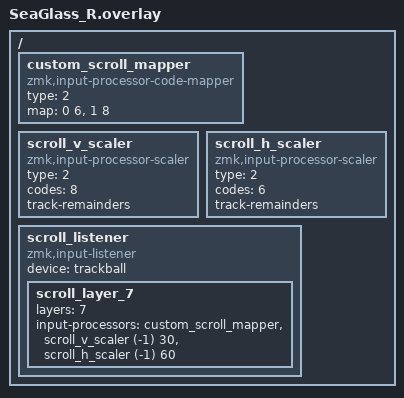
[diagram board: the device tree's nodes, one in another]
/ {
    /* 1. 移動をスクロールに変換するマッパー */
    custom_scroll_mapper: custom_scroll_mapper {
        compatible = "zmk,input-processor-code-mapper";
        #input-processor-cells = <0>;
        type = <2>; 
        map = <0 6>, <1 8>;
    };

    /* =======================================
       2. 感度（距離）を調整するスケーラーを2つに分割！
       ======================================= */
       
    /* ▼ 縦スクロール（上下）用の調整器 */
    scroll_v_scaler: scroll_v_scaler {
        compatible = "zmk,input-processor-scaler";
        #input-processor-cells = <2>;
        type = <2>;
        codes = <8>; /* 8 = 縦スクロール */
        track-remainders;
    };

    /* ▼ 横スクロール（左右）用の調整器 */
    scroll_h_scaler: scroll_h_scaler {
        compatible = "zmk,input-processor-scaler";
        #input-processor-cells = <2>;
        type = <2>;
        codes = <6>; /* 6 = 横スクロール(Pan) */
        track-remainders;
    };

    /* 3. スクロール動作の設定 */
    scroll_listener {
        compatible = "zmk,input-listener";
        device = <&trackball>; 

        /* レイヤー7に設定 */
        scroll_layer_7 {
            layers = <7>; 
            
            /* 
               マッパーで変換した後、縦と横それぞれのスケーラーを通します。
               以下の数字をいじって、お好みの距離に調整してください！
            */
            input-processors = 
                <&custom_scroll_mapper>, 
                <&scroll_v_scaler (-1) 30>,  /* ◀︎ 縦の感度（例: 1/4倍） */
                <&scroll_h_scaler (-1) 60>; /* ◀︎ 横の感度（例: 誤爆防止で1/10倍と鈍めに設定） */
        };
    };
};
